# ISP_H3A register map
Vendor: Texas Instruments
Peripheral module from a debugger description file (folder omap36xx).
Registers are 32-bit, read-write, reset 0x0 unless marked. A register's access mark holds for its fields unless they carry their own. Offsets are as the file gives them; lines under a group give offsets from that group; [hi:lo] are bit positions; {n}, {i} and the like mark numbered series; 'fields as' and 'values as' point back to an identical list; <NAME> marks a mode.

## ISP_H3A
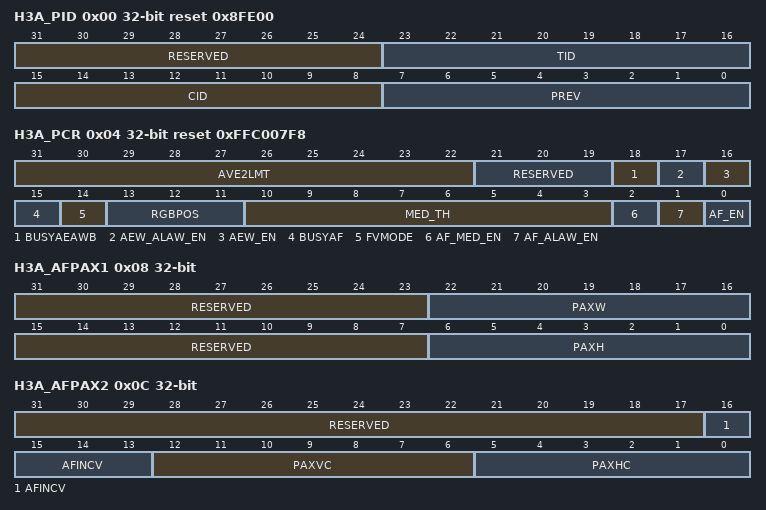
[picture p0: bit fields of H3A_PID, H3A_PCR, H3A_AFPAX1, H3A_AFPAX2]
0x00 H3A_PID ro reset 0x8FE00 (reset mask 0xFFFFFF00) — PERIPHERAL ID REGISTER
  [31:24] RESERVED — Write 0s for future compatibility. Reads returns 0.
  [23:16] TID — Peripheral identification: H3A module
  [15:8] CID — Class identification: Camera ISP
  [7:0] PREV — Peripheral revision number
0x04 H3A_PCR access per field reset 0xFFC007F8 — PERIPHERAL CONTROL REGISTER
  [31:22] AVE2LMT rw — AE AWB saturation limit. All pixels in a block are compared to this limit. If one pixel is above the limit, the block is considered saturated.
  [21:19] RESERVED rw — Write 0s for future compatibility.Reads returns 0.
  [18] BUSYAEAWB ro — AE AWB busy
    0=AE AWB not busy; 1=AE AWB busy
  [17] AEW_ALAW_EN rw — AE AWB A-Law enable
    0=Disable AE AWB A-Law table; 1=Disable AE AWB A-Law table
  [16] AEW_EN rw — AE AWB enable
    0=Disable AE AWB; 1=Enable AE AWB
  [15] BUSYAF ro — AF busy
    0=AF not busy; 1=AF busy
  [14] FVMODE rw — Focus value accumulation mode
    0=Sum mode; 1=Peak mode
  [13:11] RGBPOS rw — RGB pixel position in the AF windows
    0=GR and GB as Bayer pattern; 1=RG and GB as Bayer pattern; 2=GR and BG as Bayer pattern; 3=RG and BG as Bayer pattern; 4=GG and RB as Bayer pattern; 5=RB and GG as Bayer pattern
  [10:3] MED_TH rw — Median filter threshold
  [2] AF_MED_EN rw — AF median filter enable
    0=Disable autofocus median filter; 1=Enable autofocus median filter
  [1] AF_ALAW_EN rw — AF A-Law table enable
    0=Disable autofocus A-Law table; 1=Enable autofocus A-Law table
  [0] AF_EN rw — AF enable
    0=Disable autofocus; 1=Enable autofocus
0x08 H3A_AFPAX1 — AF PAXEL CONFIGURATION
  [31:23] RESERVED — Write 0s for future compatibility.Reads returns 0.
  [22:16] PAXW — Paxel width. The paxel width is set by 2 x (PAXW+1). The paxel-width range varies from 2 to 256. The paxel width must be set to a minimum value of 16 pixels.
  [15:7] RESERVED — Write 0s for future compatibility.Reads returns 0.
  [6:0] PAXH — Paxel height. The paxel height is set by 2 x (PAXH+1). The paxel-height range varies from 2 to 256.
0x0C H3A_AFPAX2 — AF PAXEL CONFIGURATION
  [31:17] RESERVED — Write 0s for future compatibility.Reads returns 0.
  [16:13] AFINCV — AF line increments. The number of lines to skip in a paxel is set by 2 x (AFINCV+1).
  [12:6] PAXVC — Paxel count in the vertical direction. The number of paxels in the vertical direction is set by PAXVC+1. It is illegal to have more than 128 paxels in the vertical direction. We have: 0= PAXVC = 127.
  [5:0] PAXHC — Paxel count in the horizontal direction. The number of paxels in the horizontal direction is set by PAXHC+1. It is illegal to have more than 36 paxels in the horizontal direction. We have: 0= PAXHC = 35.
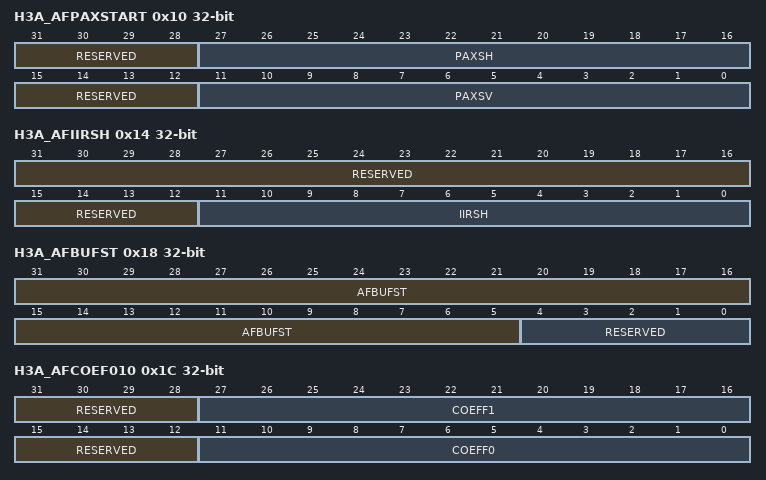
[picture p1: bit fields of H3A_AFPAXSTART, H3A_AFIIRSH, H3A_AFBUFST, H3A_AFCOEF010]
0x10 H3A_AFPAXSTART — AF PAXEL START POSITION REGISTER
  [31:28] RESERVED — Write 0s for future compatibility.Reads returns 0.
  [27:16] PAXSH — AF paxel horizontal start position. Sets the horizontal position for the first pixel. The range is 1 to 4095. PAXSH must be equal to or greater than (H3A_AFIIRSH.AFIIRSH + 1).
  [15:12] RESERVED — Write 0s for future compatibility.Reads returns 0.
  [11:0] PAXSV — AF paxel vertical start position. Sets the vertical position for the first pixel. The range is 0 to 4095.
0x14 H3A_AFIIRSH — AF IIR HORIZONTAL START POSITION REGISTER
  [31:12] RESERVED — Write 0s for future compatibility.Reads returns 0.
  [11:0] IIRSH — AF IIR horizontal start position. The range is 0 to 4095. When the horizontal position of a line equals this value the shift registers are cleared on the next pixel.
0x18 H3A_AFBUFST — AF MEMORY ADDRESS
  [31:5] AFBUFST — Address
  [4:0] RESERVED — Write 0s for future compatibility.Reads returns 0.
0x1C H3A_AFCOEF010 — IIR FILTER COEF DATA REGISTER - SET 0
  [31:28] RESERVED — Write 0s for future compatibility.Reads returns 0.
  [27:16] COEFF1 — AF IIR filter coefficient 1 (set0) The coefficient value is signed in S12Q6 representation. The range is -32 = coeff = 31.96875.
  [15:12] RESERVED — Write 0s for future compatibility.Reads returns 0.
  [11:0] COEFF0 — AF IIR filter coefficient 0 (set0) The coefficient value is signed in S12Q6 representation. The range is -32 = coeff = 31.96875.
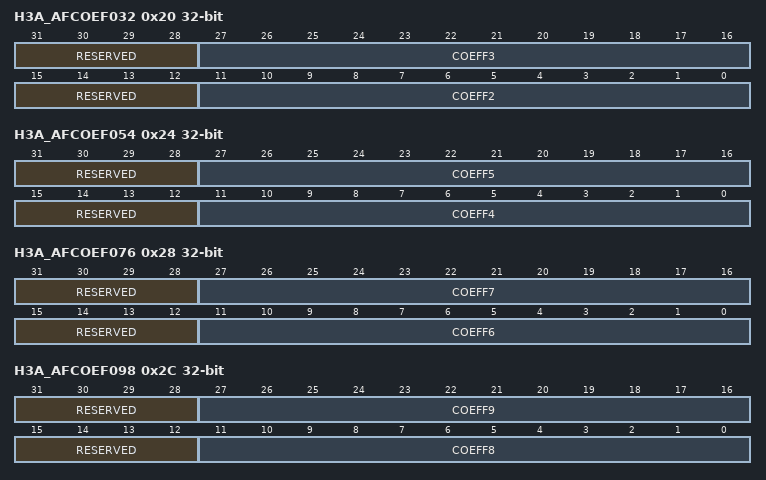
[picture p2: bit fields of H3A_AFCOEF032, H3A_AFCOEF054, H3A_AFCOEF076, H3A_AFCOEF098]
0x20 H3A_AFCOEF032 — IIR FILTER COEF DATA REGISTER - SET 0
  [31:28] RESERVED — Write 0s for future compatibility.Reads returns 0.
  [27:16] COEFF3 — AF IIR filter coefficient 3 (set0) The coefficient value is signed in S12Q6 representation. The range is -32 = coeff = 31.96875.
  [15:12] RESERVED — Write 0s for future compatibility.Reads returns 0.
  [11:0] COEFF2 — AF IIR filter coefficient 2 (set0) The coefficient value is signed in S12Q6 representation. The range is -32 = coeff = 31.96875.
0x24 H3A_AFCOEF054 — IIR FILTER COEF DATA REGISTER - SET 0
  [31:28] RESERVED — Write 0s for future compatibility.Reads returns 0.
  [27:16] COEFF5 — AF IIR filter coefficient 5 (set0) The coefficient value is signed in S12Q6 representation. The range is -32 = coeff = 31.96875.
  [15:12] RESERVED — Write 0s for future compatibility.Reads returns 0.
  [11:0] COEFF4 — AF IIR filter coefficient 4 (set0) The coefficient value is signed in S12Q6 representation. The range is -32 = coeff = 31.96875.
0x28 H3A_AFCOEF076 — IIR FILTER COEF DATA REGISTER - SET 0
  [31:28] RESERVED — Write 0s for future compatibility.Reads returns 0.
  [27:16] COEFF7 — AF IIR filter coefficient 7 (set0) The coefficient value is signed in S12Q6 representation. The range is -32 = coeff = 31.96875.
  [15:12] RESERVED — Write 0s for future compatibility.Reads returns 0.
  [11:0] COEFF6 — AF IIR filter coefficient 6 (set0) The coefficient value is signed in S12Q6 representation. The range is -32 = coeff = 31.96875.
0x2C H3A_AFCOEF098 — IIR FILTER COEF DATA REGISTER - SET 0
  [31:28] RESERVED — Write 0s for future compatibility.Reads returns 0.
  [27:16] COEFF9 — AF IIR filter coefficient 8 (set0) The coefficient value is signed in S12Q6 representation. The range is -32 = coeff = 31.96875.
  [15:12] RESERVED — Write 0s for future compatibility.Reads returns 0.
  [11:0] COEFF8 — AF IIR filter coefficient 9 (set0) The coefficient value is signed in S12Q6 representation. The range is -32 = coeff = 31.96875.
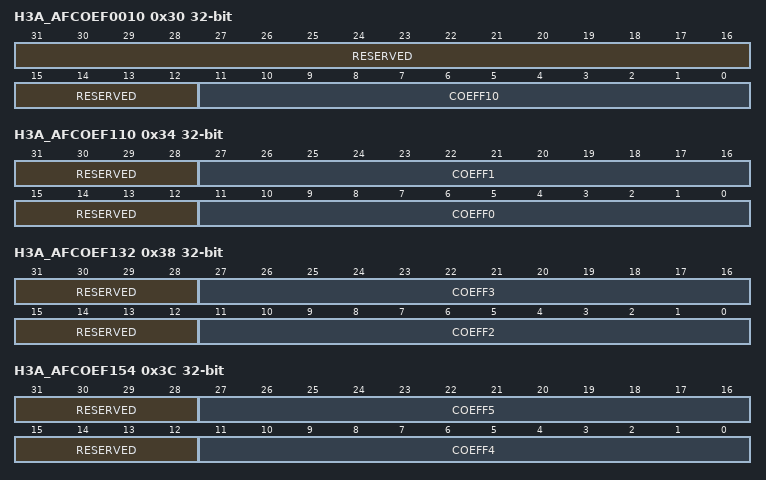
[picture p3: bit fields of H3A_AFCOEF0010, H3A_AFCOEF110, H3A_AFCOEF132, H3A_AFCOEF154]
0x30 H3A_AFCOEF0010 — IIR FILTER COEF DATA REGISTER - SET 0
  [31:12] RESERVED — Write 0s for future compatibility.Reads returns 0.
  [11:0] COEFF10 — AF IIR filter coefficient 10 (set0) The coefficient value is signed in S12Q6 representation. The range is -32 = coeff = 31.96875.
0x34 H3A_AFCOEF110 — IIR FILTER COEF DATA REGISTER - SET 1
  [31:28] RESERVED — Write 0s for future compatibility.Reads returns 0.
  [27:16] COEFF1 — AF IIR filter coefficient 1 (set1) The coefficient value is signed in S12Q6 representation. The range is -32 = coeff = 31.96875.
  [15:12] RESERVED — Write 0s for future compatibility.Reads returns 0.
  [11:0] COEFF0 — AF IIR filter coefficient 0 (set1) The coefficient value is signed in S12Q6 representation. The range is -32 = coeff = 31.96875.
0x38 H3A_AFCOEF132 — IIR FILTER COEF DATA REGISTER - SET 1
  [31:28] RESERVED — Write 0s for future compatibility.Reads returns 0.
  [27:16] COEFF3 — AF IIR filter coefficient 3 (set1) The coefficient value is signed in S12Q6 representation. The range is -32 = coeff = 31.96875.
  [15:12] RESERVED — Write 0s for future compatibility.Reads returns 0.
  [11:0] COEFF2 — AF IIR filter coefficient 2 (set1) The coefficient value is signed in S12Q6 representation. The range is -32 = coeff = 31.96875.
0x3C H3A_AFCOEF154 — IIR FILTER COEF DATA REGISTER - SET 1
  [31:28] RESERVED — Write 0s for future compatibility.Reads returns 0.
  [27:16] COEFF5 — AF IIR filter coefficient 5 (set1) The coefficient value is signed in S12Q6 representation. The range is -32 = coeff = 31.96875.
  [15:12] RESERVED — Write 0s for future compatibility.Reads returns 0.
  [11:0] COEFF4 — AF IIR filter coefficient 4 (set1) The coefficient value is signed in S12Q6 representation. The range is -32 = coeff = 31.96875.
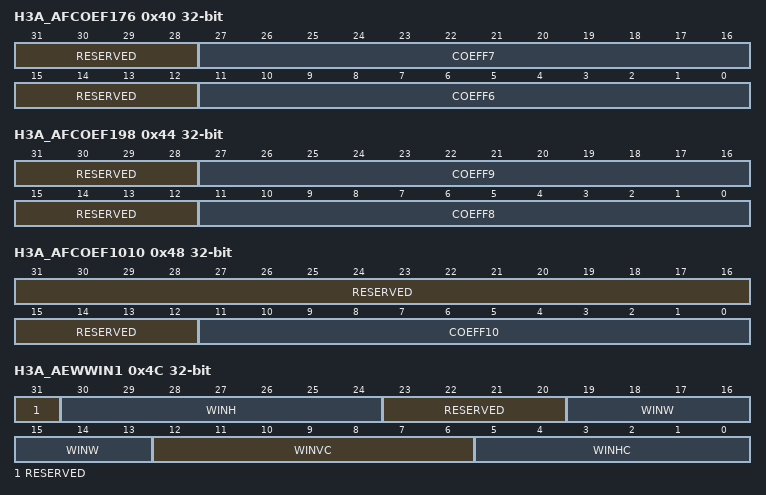
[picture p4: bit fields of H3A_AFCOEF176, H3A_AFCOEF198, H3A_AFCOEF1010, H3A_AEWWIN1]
0x40 H3A_AFCOEF176 — IIR FILTER COEF DATA REGISTER - SET 1
  [31:28] RESERVED — Write 0s for future compatibility.Reads returns 0.
  [27:16] COEFF7 — AF IIR filter coefficient 7 (set1) The coefficient value is signed in S12Q6 representation. The range is -32 = coeff = 31.96875.
  [15:12] RESERVED — Write 0s for future compatibility.Reads returns 0.
  [11:0] COEFF6 — AF IIR filter coefficient 6 (set1) The coefficient value is signed in S12Q6 representation. The range is -32 = coeff = 31.96875.
0x44 H3A_AFCOEF198 — IIR FILTER COEF DATA REGISTER - SET 1
  [31:28] RESERVED — Write 0s for future compatibility.Reads returns 0.
  [27:16] COEFF9 — AF IIR filter coefficient 9 (set0) The coefficient value is signed in S12Q6 representation. The range is -32 = coeff = 31.96875.
  [15:12] RESERVED — Write 0s for future compatibility.Reads returns 0.
  [11:0] COEFF8 — AF IIR filter coefficient 8 (set0) The coefficient value is signed in S12Q6 representation. The range is -32 = coeff = 31.96875.
0x48 H3A_AFCOEF1010 — IIR FILTER COEF DATA REGISTER - SET 1
  [31:12] RESERVED — Write 0s for future compatibility.Reads returns 0.
  [11:0] COEFF10 — AF IIR filter coefficient 10 (set1) The coefficient value is signed in S12Q6 representation. The range is -32 = coeff = 31.96875.
0x4C H3A_AEWWIN1 — AE AWB CONTROL REGISTER
  [31] RESERVED — Write 0s for future compatibility.Reads returns 0.
  [30:24] WINH — AE AWB window height. The window height is given by 2 x (WINH+1). The final value ranges between 2 to 256 (even values only).
  [23:20] RESERVED — Write 0s for future compatibility.Reads returns 0.
  [19:13] WINW — AE AWB window width. The window width is given by 2 x (WINW+1). The final value ranges between 2 to 256 (even values only).
  [12:6] WINVC — AE AWB vertical window count The number of windows in the vertical direction is set by WINVC + 1. The maximum number of vertical windows in a frame must not exceed 128.
  [5:0] WINHC — AE AWB horizontal window count. The number of horizontal windows is set by WINHC + 1. The maximum number of horizontal windows in a frame must not exceed 36.
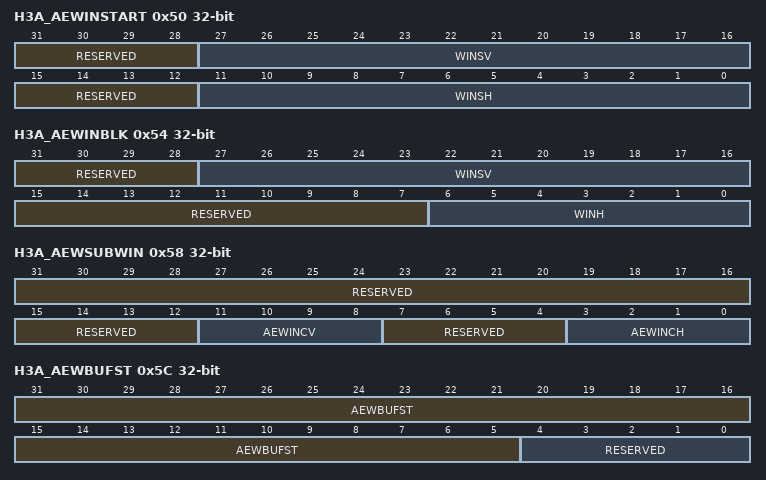
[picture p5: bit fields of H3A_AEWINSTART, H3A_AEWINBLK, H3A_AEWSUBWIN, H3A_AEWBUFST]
0x50 H3A_AEWINSTART — AE AWB START POSITION REGISTER
  [31:28] RESERVED — Write 0s for future compatibility.Reads returns 0.
  [27:16] WINSV — AE AWB vertical window start position. Sets the first line for the first window. The range is 0 to 4095.
  [15:12] RESERVED — Write 0s for future compatibility.Reads returns 0.
  [11:0] WINSH — AE AWB horizontal window start position. Sets the horizontal position for the first window on each line. The range is 0 to 4095.
0x54 H3A_AEWINBLK — BLACK LINE REGISTER
  [31:28] RESERVED — Write 0s for future compatibility.Reads returns 0.
  [27:16] WINSV — AE AWB vertical window start position for the single black line of windows. Sets the first line for the single black line of windows. The range is 0 to 4095. Note that the horizontal start and the horizontal number of windows is similar to the regular windows.
  [15:7] RESERVED — Write 0s for future compatibility.Reads returns 0.
  [6:0] WINH — AE AWB window height for the single black line of windows. The window height is set by 2 x (WINH + 1). The range is 2 to 256 (even values only).
0x58 H3A_AEWSUBWIN — AE AWB REGISTER
  [31:12] RESERVED — Write 0s for future compatibility.Reads returns 0.
  [11:8] AEWINCV — AE AWB vertical sampling point increment. Sets the vertical distance between subsamples. The increment is set by 2 x (AEWINCV+1). The range is 2 to 32 (even values only).
  [7:4] RESERVED — Write 0s for future compatibility.Reads returns 0.
  [3:0] AEWINCH — AE AWB horizontal sampling point increment. Sets the horizontal distance between subsamples. The increment is set by 2 x (AEWINCH+1). The range is 2 to 32 (even values only).
0x5C H3A_AEWBUFST — AE AWB MEMORY ADDRESS
  [31:5] AEWBUFST — AE AWB memory start address The start address in memory where the AE/AWB data are written. This field can be modified even when the AE/AWB submodule is busy. The change takes place only for the next frame. However, register reads always give the latest value.
  [4:0] RESERVED — Write 0s for future compatibility.Reads returns 0.
